# MKE16F16 register map
Vendor: Freescale Semiconductor, Inc.; Series: Kinetis_E; File version: 1.6
CPU: CM4 r0p1, little endian, no MPU, FPU, VTOR, 4 interrupt priority bits
Registers are 32-bit, read-write, reset 0x0 unless marked. A register's access mark holds for its fields unless they carry their own. Offsets are from the block's base; [hi:lo] are bit positions.

## WDOG — Watchdog timer
Base 0x40052000; register names take the prefix WDOG_
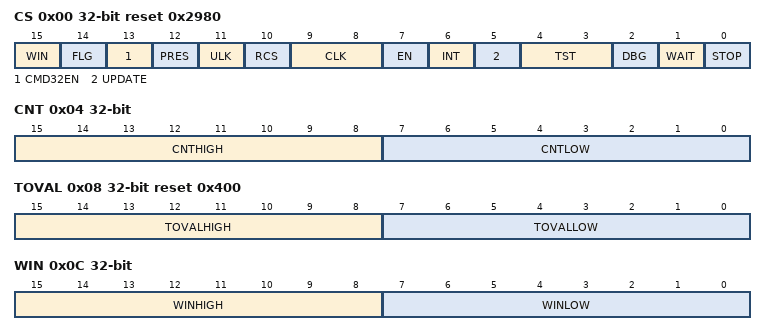
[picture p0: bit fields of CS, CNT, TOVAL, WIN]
0x00 CS reset 0x2980 — Watchdog Control and Status Register
  [15] WIN — Watchdog Window
    0=Window mode disabled; 1=Window mode enabled
  [14] FLG — Watchdog Interrupt Flag
    0=No interrupt occurred; 1=An interrupt occurred
  [13] CMD32EN — Enables or disables WDOG support for 32-bit (or 16-bit or 8-bit) refresh/unlock command write words
    0=Disables support for 32-bit (or 16-bit or 8-bit) refresh/unlock command write words; 1=Enables support for 32-bit (or 16-bit or 8-bit) refresh/unlock command write words
  [12] PRES — Watchdog prescaler
    0=256 prescaler disabled; 1=256 prescaler enabled
  [11] ULK ro — Unlock status
    0=WDOG is locked; 1=WDOG is unlocked
  [10] RCS ro — Reconfiguration Success
    0=Reconfiguring WDOG; 1=Reconfiguration is successful
  [9:8] CLK — Watchdog Clock
    0=Bus clock; 1=LPO clock (128k LPO, 32k LPO, 1k LPO, or 32k OSC), whose selection is controlled via SIM_LPOCLKS[LPOCLKSEL]; 2=System oscillator clock (SOSC, from SCG); 3=Slow internal reference clock (SIRC, from SCG)
  [7] EN — Watchdog Enable
    0=Watchdog disabled; 1=Watchdog enabled
  [6] INT — Watchdog Interrupt
    0=Watchdog interrupts are disabled. Watchdog resets are not delayed.; 1=Watchdog interrupts are enabled. Watchdog resets are delayed by 128 bus clocks from the interrupt vector fetch.
  [5] UPDATE — Allow updates
    0=Updates not allowed. After the initial configuration, the watchdog cannot be later modified without forcing a reset.; 1=Updates allowed. Software can modify the watchdog configuration registers within 128 bus clocks after performing the unlock write sequence.
  [4:3] TST — Watchdog Test
    0=Watchdog test mode disabled; 1=Watchdog user mode enabled. (Watchdog test mode disabled.) After testing the watchdog, software should use this setting to indicate that the watchdog is functioning normally in user mode.; 2=Watchdog test mode enabled, only the low byte is used. CNT[CNTLOW] is compared with TOVAL[TOVALLOW].; 3=Watchdog test mode enabled, only the high byte is used. CNT[CNTHIGH] is compared with TOVAL[TOVALHIGH].
  [2] DBG — Debug Enable
    0=Watchdog disabled in chip debug mode; 1=Watchdog enabled in chip debug mode
  [1] WAIT — Wait Enable
    0=Watchdog disabled in chip wait mode; 1=Watchdog enabled in chip wait mode
  [0] STOP — Stop Enable
    0=Watchdog disabled in chip stop mode; 1=Watchdog enabled in chip stop mode
0x04 CNT — Watchdog Counter Register
  [15:8] CNTHIGH — High byte of the Watchdog Counter
  [7:0] CNTLOW — Low byte of the Watchdog Counter
0x08 TOVAL reset 0x400 — Watchdog Timeout Value Register
  [15:8] TOVALHIGH — High byte of the timeout value
  [7:0] TOVALLOW — Low byte of the timeout value
0x0C WIN — Watchdog Window Register
  [15:8] WINHIGH — High byte of Watchdog Window
  [7:0] WINLOW — Low byte of Watchdog Window

## PWT — Pulse Width Timer
Base 0x40056000; register names take the prefix PWT_
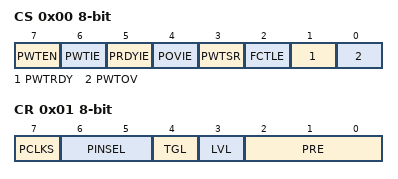
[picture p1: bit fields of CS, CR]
0x00 CS 8-bit — Pulse Width Timer Control and Status Register
  [7] PWTEN — PWT Module Enable
    0=The PWT is disabled; 1=The PWT is enabled
  [6] PWTIE — PWT Module Interrupt Enable
    0=Disables the PWT to generate interrupt; 1=Enables the PWT to generate interrupt
  [5] PRDYIE — PWT Pulse Width Data Ready Interrupt Enable
    0=Disable PWT to generate interrupt when PWTRDY is set; 1=Enable PWT to generate interrupt when PWTRDY is set
  [4] POVIE — PWT Counter Overflow Interrupt Enable
    0=Disable PWT to generate interrupt when PWTOV is set; 1=Enable PWT to generate interrupt when PWTOV is set
  [3] PWTSR wo — PWT Soft Reset
    0=No action taken; 1=Writing 1 to this field will perform soft reset to PWT
  [2] FCTLE — First counter load enable after enable
    0=Do not load the first counter values to corresponding registers; 1=Load the first coutner value to corresponding registers depended by the PWTIN level
  [1] PWTRDY — PWT Pulse Width Valid
    0=PWT pulse width register(s) is not up-to-date; 1=PWT pulse width register(s) has been updated
  [0] PWTOV — PWT Counter Overflow
    0=PWT counter no overflow; 1=PWT counter runs from 0xFFFF to 0x0000
0x01 CR 8-bit — Pulse Width Timer Control Register
  [7] PCLKS — PWT Clock Source Selection
    0=BUS_CLK is selected as the clock source of PWT counter; 1=Alternative clock is selected as the clock source of PWT counter
  [6:5] PINSEL — PWT Pulse Inputs Selection
    0=PWTIN[0] is enabled; 1=PWTIN[1] is enabled; 2=PWTIN[2] enabled; 3=PWTIN[3] enabled
  [4] TGL — PWTIN states Toggled from last state
    0=The selected PWTIN hasn't changed its original states from last time; 1=The selected PWTIN has toggled its states
  [3] LVL ro — PWTIN Level when Overflows
  [2:0] PRE — PWT Clock Prescaler (CLKPRE) Setting
    0=Clock divided by 1; 1=Clock divided by 2; 2=Clock divided by 4; 3=Clock divided by 8; 4=Clock divided by 16; 5=Clock divided by 32; 6=Clock divided by 64; 7=Clock divided by 128
0x02 PPH 8-bit ro — Pulse Width Timer Positive Pulse Width Register: High
  [7:0] PPWH — Positive Pulse Width[15:8]
0x03 PPL 8-bit ro — Pulse Width Timer Positive Pulse Width Register: Loq
  [7:0] PPWL — Positive Pulse Width[7:0]
0x04 NPH 8-bit ro — Pulse Width Timer Negative Pulse Width Register: High
  [7:0] NPWH — Negative Pulse Width[15:8]
0x05 NPL 8-bit ro — Pulse Width Timer Negative Pulse Width Register: Low
  [7:0] NPWL — Negative Pulse Width[7:0]
0x06 CNTH 8-bit ro — Pulse Width Timer Counter Register: High
  [7:0] PWTH — PWT counter[15:8]
0x07 CNTL 8-bit ro — Pulse Width Timer Counter Register: Low
  [7:0] PWTL — PWT counter[7:0]
